# STM32H573 register map
File version: 0.4
CPU: CM33 r0p0, little endian, MPU, FPU, 4 interrupt priority bits
Registers are 32-bit, read-write, reset 0x0 unless marked. A register's access mark holds for its fields unless they carry their own. Offsets are from the block's base; [hi:lo] are bit positions; {n}, {i} and the like mark numbered series.

## TIM1 — Advanced-control timers
Base 0x40012C00
Same registers: TIM8 0x40013400, SEC_TIM1 0x50012C00, SEC_TIM8 0x50013400
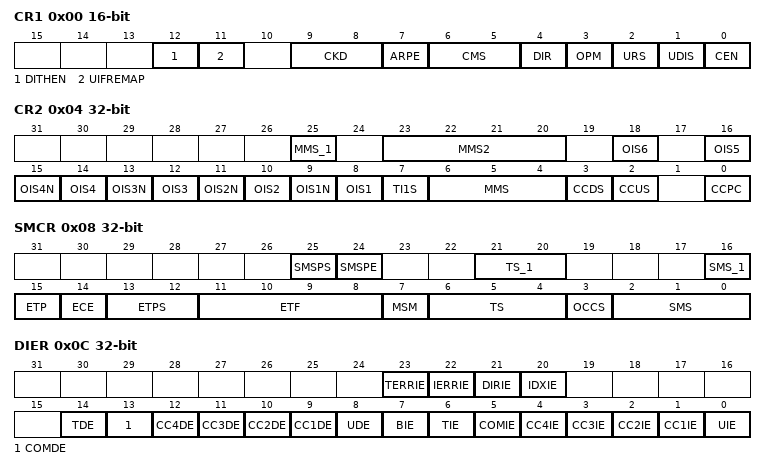
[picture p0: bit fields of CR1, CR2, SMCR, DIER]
0x00 CR1 16-bit — TIM1 control register 1
  [12] DITHEN — Dithering enable Note: The DITHEN bit can only be modified when CEN bit is reset.
  [11] UIFREMAP — UIF status bit remapping
  [9:8] CKD — Clock division This bit-field indicates the division ratio between the timer clock (tim_ker_ck) frequency and the dead-time and sampling clock (t<sub>DTS</sub>)used by the dead-time generators and the digital filters (tim_etr_in, tim_tix),
  [7] ARPE — Auto-reload preload enable
  [6:5] CMS — Center-aligned mode selection Note: It is not allowed to switch from edge-aligned mode to center-aligned mode as long as the counter is enabled (CEN=1)
  [4] DIR — Direction Note: This bit is read only when the timer is configured in Center-aligned mode or Encoder mode.
  [3] OPM — One-pulse mode
  [2] URS — Update request source This bit is set and cleared by software to select the UEV event sources. Counter overflow/underflow Setting the UG bit Update generation through the slave mode controller
  [1] UDIS — Update disable This bit is set and cleared by software to enable/disable UEV event generation. Counter overflow/underflow Setting the UG bit Update generation through the slave mode controller Buffered registers are then loaded with their preload values.
  [0] CEN — Counter enable Note: External clock, gated mode and encoder mode can work only if the CEN bit has been previously set by software. However trigger mode can set the CEN bit automatically by hardware.
0x04 CR2 — TIM1 control register 2
  [25] MMS_1 — MMS[3]
  [23:20] MMS2 — Master mode selection 2 These bits allow the information to be sent to ADC for synchronization (tim_trgo2) to be selected. The combination is as follows: Note: The clock of the slave timer or ADC must be enabled prior to receive events from the master timer, and must not be changed on-the-fly while triggers are received from the master timer.
  [18] OIS6 — Output idle state 6 (tim_oc6 output) Refer to OIS1 bit
  [16] OIS5 — Output idle state 5 (tim_oc5 output) Refer to OIS1 bit
  [15] OIS4N — Output idle state 4 (tim_oc4n output) Refer to OIS1N bit
  [14] OIS4 — Output idle state 4 (tim_oc4 output) Refer to OIS1 bit
  [13] OIS3N — Output idle state 3 (tim_oc3n output) Refer to OIS1N bit
  [12] OIS3 — Output idle state 3 (tim_oc3n output) Refer to OIS1 bit
  [11] OIS2N — Output idle state 2 (tim_oc2n output) Refer to OIS1N bit
  [10] OIS2 — Output idle state 2 (tim_oc2 output) Refer to OIS1 bit
  [9] OIS1N — Output idle state 1 (tim_oc1n output) Note: This bit can not be modified as long as LOCK level 1, 2 or 3 has been programmed (LOCK bits in TIMx_BDTR register).
  [8] OIS1 — Output idle state 1 (tim_oc1 output) Note: This bit can not be modified as long as LOCK level 1, 2 or 3 has been programmed (LOCK bits in TIMx_BDTR register).
  [7] TI1S — tim_ti1 selection
  [6:4] MMS — MMS[2:0]: Master mode selection These bits select the information to be sent in master mode to slave timers for synchronization (tim_trgo). The combination is as follows: Other codes reserved Note: The clock of the slave timer or ADC must be enabled prior to receive events from the master timer, and must not be changed on-the-fly while triggers are received from the master timer.
  [3] CCDS — Capture/compare DMA selection
  [2] CCUS — Capture/compare control update selection Note: This bit acts only on channels that have a complementary output.
  [0] CCPC — Capture/compare preloaded control Note: This bit acts only on channels that have a complementary output.
0x08 SMCR — TIM1 slave mode control register
  [25] SMSPS — SMS preload source This bit selects whether the events that triggers the SMS[3:0] bitfield transfer from preload to active
  [24] SMSPE — SMS preload enable This bit selects whether the SMS[3:0] bitfield is preloaded
  [21:20] TS_1 — TS[4:3]
  [16] SMS_1 — SMS[3]
  [15] ETP — External trigger polarity This bit selects whether tim_etr_in or tim_etr_in is used for trigger operations
  [14] ECE — External clock enable This bit enables External clock mode 2. Note: Setting the ECE bit has the same effect as selecting external clock mode 1 with tim_trgi connected to tim_etrf (SMS=111 and TS=00111). It is possible to simultaneously use external clock mode 2 with the following slave modes: reset mode, gated mode and trigger mode. Nevertheless, tim_trgi must not be connected to tim_etrf in this case (TS bits must not be 00111). Note: If external clock mode 1 and external clock mode 2 are enabled at the same time, the external clock input is tim_etrf.
  [13:12] ETPS — External trigger prescaler External trigger signal tim_etrp frequency must be at most 1/4 of TIMxCLK frequency. A prescaler can be enabled to reduce tim_etrp frequency. It is useful when inputting fast external clocks on tim_etr_in.
  [11:8] ETF — External trigger filter This bit-field then defines the frequency used to sample tim_etrp signal and the length of the digital filter applied to tim_etrp. The digital filter is made of an event counter in which N consecutive events are needed to validate a transition on the output:
  [7] MSM — Master/slave mode
  [6:4] TS — TS[2:0]: Trigger selection This bitfield is combined with TS[4:3] bits. This bit-field selects the trigger input to be used to synchronize the counter. Others: Reserved See Table 605: TIMx internal trigger connection for more details on tim_itrx meaning for each Timer. Note: These bits must be changed only when they are not used (e.g. when SMS=000) to avoid wrong edge detections at the transition.
  [3] OCCS — OCREF clear selection This bit is used to select the OCREF clear source.
  [2:0] SMS — SMS[2:0]: Slave mode selection When external signals are selected the active edge of the trigger signal (tim_trgi) is linked to the polarity selected on the external input (see Input Control register and Control Register description. Note: The gated mode must not be used if tim_ti1f_ed is selected as the trigger input (TS=00100). Indeed, tim_ti1f_ed outputs 1 pulse for each transition on TI1F, whereas the gated mode checks the level of the trigger signal. Note: The clock of the slave peripherals (timer, ADC, ...) receiving the tim_trgo or the tim_trgo2 signals must be enabled prior to receive events from the master timer, and the clock frequency (prescaler) must not be changed on-the-fly while triggers are received from the master timer.
0x0C DIER — TIM1 DMA/interrupt enable register
  [23] TERRIE — Transition error interrupt enable
  [22] IERRIE — Index error interrupt enable
  [21] DIRIE — Direction change interrupt enable
  [20] IDXIE — Index interrupt enable
  [14] TDE — Trigger DMA request enable
  [13] COMDE — COM DMA request enable
  [n+8] CC{n}DE (n=1..4) — Capture/compare {n} DMA request enable
  [8] UDE — Update DMA request enable
  [7] BIE — Break interrupt enable
  [6] TIE — Trigger interrupt enable
  [5] COMIE — COM interrupt enable
  [n] CC{n}IE (n=1..4) — Capture/compare {n} interrupt enable
  [0] UIE — Update interrupt enable
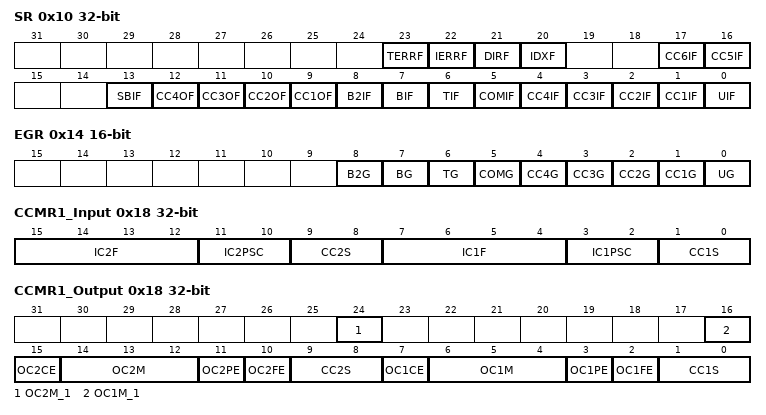
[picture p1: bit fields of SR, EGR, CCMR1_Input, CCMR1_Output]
0x10 SR — TIM1 status register
  [23] TERRF — Transition error interrupt flag This flag is set by hardware when a transition error is detected in encoder mode. It is cleared by software by writing it to ‘0’.
  [22] IERRF — Index error interrupt flag This flag is set by hardware when an index error is detected. It is cleared by software by writing it to ‘0’.
  [21] DIRF — Direction change interrupt flag This flag is set by hardware when the direction changes in encoder mode (DIR bit value in TIMx_CR is changing). It is cleared by software by writing it to ‘0’.
  [20] IDXF — Index interrupt flag This flag is set by hardware when an index event is detected. It is cleared by software by writing it to ‘0’.
  [17] CC6IF — Compare 6 interrupt flag Refer to CC1IF description Note: Channel 6 can only be configured as output.
  [16] CC5IF — Compare 5 interrupt flag Refer to CC1IF description Note: Channel 5 can only be configured as output.
  [13] SBIF — System break interrupt flag This flag is set by hardware as soon as the system break input goes active. It can be cleared by software if the system break input is not active. This flag must be reset to re-start PWM operation.
  [12] CC4OF — Capture/compare 4 overcapture flag Refer to CC1OF description
  [11] CC3OF — Capture/compare 3 overcapture flag Refer to CC1OF description
  [10] CC2OF — Capture/compare 2 overcapture flag Refer to CC1OF description
  [9] CC1OF — Capture/compare 1 overcapture flag This flag is set by hardware only when the corresponding channel is configured in input capture mode. It is cleared by software by writing it to ‘0’.
  [8] B2IF — Break 2 interrupt flag This flag is set by hardware as soon as the break 2 input goes active. It can be cleared by software if the break 2 input is not active.
  [7] BIF — Break interrupt flag This flag is set by hardware as soon as the break input goes active. It can be cleared by software if the break input is not active.
  [6] TIF — Trigger interrupt flag This flag is set by hardware on the TRG trigger event (active edge detected on tim_trgi input when the slave mode controller is enabled in all modes but gated mode. It is set when the counter starts or stops when gated mode is selected. It is cleared by software.
  [5] COMIF — COM interrupt flag This flag is set by hardware on COM event (when capture/compare Control bits - CCxE, CCxNE, OCxM - have been updated). It is cleared by software.
  [4] CC4IF — Capture/compare 4 interrupt flag Refer to CC1IF description
  [3] CC3IF — Capture/compare 3 interrupt flag Refer to CC1IF description
  [2] CC2IF — Capture/compare 2 interrupt flag Refer to CC1IF description
  [1] CC1IF — Capture/compare 1 interrupt flag This flag is set by hardware. It is cleared by software (input capture or output compare mode) or by reading the TIMx_CCR1 register (input capture mode only). If channel CC1 is configured as output: this flag is set when the content of the counter TIMx_CNT matches the content of the TIMx_CCR1 register. When the content of TIMx_CCR1 is greater than the content of TIMx_ARR, the CC1IF bit goes high on the counter overflow (in up-counting and up/down-counting modes) or underflow (in downcounting mode). There are 3 possible options for flag setting in center-aligned mode, refer to the CMS bits in the TIMx_CR1 register for the full description. If channel CC1 is configured as input: this bit is set when counter value has been captured in TIMx_CCR1 register (an edge has been detected on IC1, as per the edge sensitivity defined with the CC1P and CC1NP bits setting, in TIMx_CCER).
  [0] UIF — Update interrupt flag This bit is set by hardware on an update event. It is cleared by software. At overflow or underflow regarding the repetition counter value (update if repetition counter = 0) and if the UDIS=0 in the TIMx_CR1 register. When CNT is reinitialized by software using the UG bit in TIMx_EGR register, if URS=0 and UDIS=0 in the TIMx_CR1 register. When CNT is reinitialized by a trigger event (refer to Section 65.6.3: TIM1 slave mode control register (TIM1_SMCR)), if URS=0 and UDIS=0 in the TIMx_CR1 register.
0x14 EGR 16-bit wo — TIM1 event generation register
  [8] B2G — Break 2 generation This bit is set by software in order to generate an event, it is automatically cleared by hardware.
  [7] BG — Break generation This bit is set by software in order to generate an event, it is automatically cleared by hardware.
  [6] TG — Trigger generation This bit is set by software in order to generate an event, it is automatically cleared by hardware.
  [5] COMG — Capture/compare control update generation This bit can be set by software, it is automatically cleared by hardware Note: This bit acts only on channels having a complementary output.
  [4] CC4G — Capture/compare 4 generation Refer to CC1G description
  [3] CC3G — Capture/compare 3 generation Refer to CC1G description
  [2] CC2G — Capture/compare 2 generation Refer to CC1G description
  [1] CC1G — Capture/compare 1 generation This bit is set by software in order to generate an event, it is automatically cleared by hardware. If channel CC1 is configured as output: CC1IF flag is set, Corresponding interrupt or DMA request is sent if enabled. If channel CC1 is configured as input: The current value of the counter is captured in TIMx_CCR1 register. The CC1IF flag is set, the corresponding interrupt or DMA request is sent if enabled. The CC1OF flag is set if the CC1IF flag was already high.
  [0] UG — Update generation This bit can be set by software, it is automatically cleared by hardware.
0x18 CCMR1_Input — TIM1 capture/compare mode register 1 [alternate]
  [15:12] IC2F — Input capture 2 filter
  [11:10] IC2PSC — Input capture 2 prescaler
  [9:8] CC2S — Capture/compare 2 selection This bit-field defines the direction of the channel (input/output) as well as the used input. Note: CC2S bits are writable only when the channel is OFF (CC2E = ‘0’ in TIMx_CCER).
  [7:4] IC1F — Input capture 1 filter This bit-field defines the frequency used to sample tim_ti1 input and the length of the digital filter applied to tim_ti1. The digital filter is made of an event counter in which N consecutive events are needed to validate a transition on the output:
  [3:2] IC1PSC — Input capture 1 prescaler This bit-field defines the ratio of the prescaler acting on CC1 input (tim_ic1). The prescaler is reset as soon as CC1E=’0’ (TIMx_CCER register).
  [1:0] CC1S — Capture/compare 1 Selection This bit-field defines the direction of the channel (input/output) as well as the used input. Note: CC1S bits are writable only when the channel is OFF (CC1E = ‘0’ in TIMx_CCER).
0x18 CCMR1_Output (alternate view of TIM1_CCMR1_Input) — TIM1 capture/compare mode register 1 [alternate]
  [24] OC2M_1 — OC2M[3]
  [16] OC1M_1 — OC1M[3]
  [15] OC2CE — Output compare 2 clear enable
  [14:12] OC2M — OC2M[2:0]: Output compare 2 mode
  [11] OC2PE — Output compare 2 preload enable
  [10] OC2FE — Output compare 2 fast enable
  [9:8] CC2S — Capture/compare 2 selection This bit-field defines the direction of the channel (input/output) as well as the used input. Note: CC2S bits are writable only when the channel is OFF (CC2E = ‘0’ in TIMx_CCER).
  [7] OC1CE — Output compare 1 clear enable
  [6:4] OC1M — OC1M[2:0]: Output compare 1 mode These bits define the behavior of the output reference signal tim_oc1ref from which tim_oc1 and tim_oc1n are derived. tim_oc1ref is active high whereas tim_oc1 and tim_oc1n active level depends on CC1P and CC1NP bits. Note: These bits can not be modified as long as LOCK level 3 has been programmed (LOCK bits in TIMx_BDTR register) and CC1S=’00’ (the channel is configured in output). Note: In PWM mode, the OCREF level changes only when the result of the comparison changes or when the output compare mode switches from “frozen” mode to “PWM” mode. Note: On channels having a complementary output, this bit field is preloaded. If the CCPC bit is set in the TIMx_CR2 register then the OC1M active bits take the new value from the preloaded bits only when a COM event is generated.
  [3] OC1PE — Output compare 1 preload enable Note: These bits can not be modified as long as LOCK level 3 has been programmed (LOCK bits in TIMx_BDTR register) and CC1S=’00’ (the channel is configured in output).
  [2] OC1FE — Output compare 1 fast enable This bit decreases the latency between a trigger event and a transition on the timer output. It must be used in one-pulse mode (OPM bit set in TIMx_CR1 register), to have the output pulse starting as soon as possible after the starting trigger.
  [1:0] CC1S — Capture/compare 1 selection This bit-field defines the direction of the channel (input/output) as well as the used input. Note: CC1S bits are writable only when the channel is OFF (CC1E = ‘0’ in TIMx_CCER).
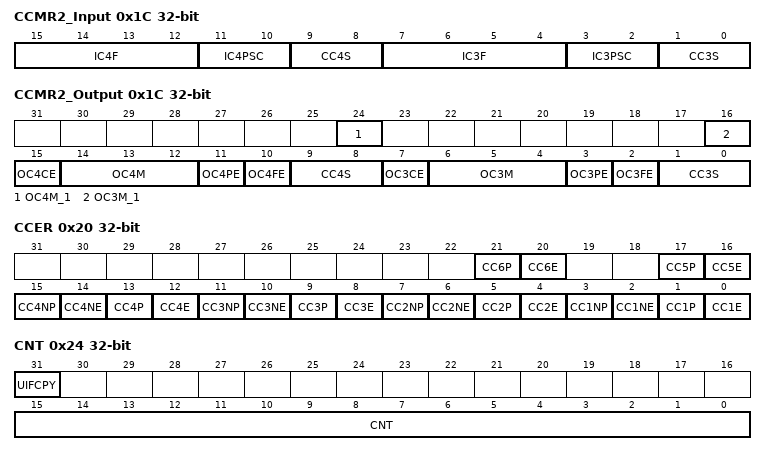
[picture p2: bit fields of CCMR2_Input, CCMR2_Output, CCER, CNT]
0x1C CCMR2_Input — TIM1 capture/compare mode register 2 [alternate]
  [15:12] IC4F — Input capture 4 filter
  [11:10] IC4PSC — Input capture 4 prescaler
  [9:8] CC4S — Capture/compare 4 selection This bit-field defines the direction of the channel (input/output) as well as the used input. Note: CC4S bits are writable only when the channel is OFF (CC4E = ‘0’ in TIMx_CCER).
  [7:4] IC3F — Input capture 3 filter
  [3:2] IC3PSC — Input capture 3 prescaler
  [1:0] CC3S — Capture/compare 3 selection This bit-field defines the direction of the channel (input/output) as well as the used input. Note: CC3S bits are writable only when the channel is OFF (CC3E = ‘0’ in TIMx_CCER).
0x1C CCMR2_Output (alternate view of TIM1_CCMR2_Input) — TIM1 capture/compare mode register 2 [alternate]
  [24] OC4M_1 — OC4M[3]
  [16] OC3M_1 — OC3M[3]
  [15] OC4CE — Output compare 4 clear enable
  [14:12] OC4M — OC4M[2:0]: Output compare 4 mode Refer to OC3M[3:0] bit description
  [11] OC4PE — Output compare 4 preload enable
  [10] OC4FE — Output compare 4 fast enable
  [9:8] CC4S — Capture/compare 4 selection This bit-field defines the direction of the channel (input/output) as well as the used input. Note: CC4S bits are writable only when the channel is OFF (CC4E = ‘0’ in TIMx_CCER).
  [7] OC3CE — Output compare 3 clear enable
  [6:4] OC3M — OC3M[2:0]: Output compare 3 mode These bits define the behavior of the output reference signal tim_oc3ref from which tim_oc3 and tim_oc3n are derived. tim_oc3ref is active high whereas tim_oc3 and tim_oc3n active level depends on CC3P and CC3NP bits. Note: These bits can not be modified as long as LOCK level 3 has been programmed (LOCK bits in TIMx_BDTR register) and CC1S=’00’ (the channel is configured in output). Note: In PWM mode, the OCREF level changes only when the result of the comparison changes or when the output compare mode switches from “frozen” mode to “PWM” mode. On channels having a complementary output, this bit field is preloaded. If the CCPC bit is set in the TIMx_CR2 register then the OC3M active bits take the new value from the preloaded bits only when a COM event is generated.
  [3] OC3PE — Output compare 3 preload enable
  [2] OC3FE — Output compare 3 fast enable
  [1:0] CC3S — Capture/compare 3 selection This bit-field defines the direction of the channel (input/output) as well as the used input. Note: CC3S bits are writable only when the channel is OFF (CC3E = ‘0’ in TIMx_CCER).
0x20 CCER — TIM1 capture/compare enable register
  [4n-3] CC{n}P (n=2..6) — Capture/compare {n} output polarity Refer to CC1P description
  [4n-4] CC{n}E (n=2..6) — Capture/compare {n} output enable Refer to CC1E description
  [15] CC4NP — Capture/compare 4 complementary output polarity Refer to CC1NP description
  [14] CC4NE — Capture/compare 4 complementary output enable Refer to CC1NE description
  [11] CC3NP — Capture/compare 3 complementary output polarity Refer to CC1NP description
  [10] CC3NE — Capture/compare 3 complementary output enable Refer to CC1NE description
  [7] CC2NP — Capture/compare 2 complementary output polarity Refer to CC1NP description
  [6] CC2NE — Capture/compare 2 complementary output enable Refer to CC1NE description
  [3] CC1NP — Capture/compare 1 complementary output polarity CC1 channel configured as output: CC1 channel configured as input: This bit is used in conjunction with CC1P to define the polarity of tim_ti1fp1 and tim_ti2fp1. Refer to CC1P description. Note: This bit is not writable as soon as LOCK level 2 or 3 has been programmed (LOCK bits in TIMx_BDTR register) and CC1S=”00” (channel configured as output). Note: On channels having a complementary output, this bit is preloaded. If the CCPC bit is set in the TIMx_CR2 register then the CC1NP active bit takes the new value from the preloaded bit only when a Commutation event is generated.
  [2] CC1NE — Capture/compare 1 complementary output enable Note: On channels having a complementary output, this bit is preloaded. If the CCPC bit is set in the TIMx_CR2 register then the CC1NE active bit takes the new value from the preloaded bit only when a Commutation event is generated.
  [1] CC1P — Capture/compare 1 output polarity When CC1 channel is configured as input, both CC1NP/CC1P bits select the active polarity of TI1FP1 and TI2FP1 for trigger or capture operations. CC1NP=0, CC1P=0: non-inverted/rising edge. The circuit is sensitive to TIxFP1 rising edge (capture or trigger operations in reset, external clock or trigger mode), TIxFP1 is not inverted (trigger operation in gated mode or encoder mode). CC1NP=0, CC1P=1: inverted/falling edge. The circuit is sensitive to TIxFP1 falling edge (capture or trigger operations in reset, external clock or trigger mode), TIxFP1 is inverted (trigger operation in gated mode or encoder mode). CC1NP=1, CC1P=1: non-inverted/both edges/ The circuit is sensitive to both TIxFP1 rising and falling edges (capture or trigger operations in reset, external clock or trigger mode), TIxFP1is not inverted (trigger operation in gated mode). This configuration must not be used in encoder mode. CC1NP=1, CC1P=0: the configuration is reserved, it must not be used. Note: This bit is not writable as soon as LOCK level 2 or 3 has been programmed (LOCK bits in TIMx_BDTR register). Note: On channels having a complementary output, this bit is preloaded. If the CCPC bit is set in the TIMx_CR2 register then the CC1P active bit takes the new value from the preloaded bit only when a Commutation event is generated.
  [0] CC1E — Capture/compare 1 output enable When CC1 channel is configured as output, the OC1 level depends on MOE, OSSI, OSSR, OIS1, OIS1N and CC1NE bits, regardless of the CC1E bits state. Refer to Table 619 for details. Note: On channels having a complementary output, this bit is preloaded. If the CCPC bit is set in the TIMx_CR2 register then the CC1E active bit takes the new value from the preloaded bit only when a Commutation event is generated.
0x24 CNT access per field — TIM1 counter
  [31] UIFCPY ro — UIF copy This bit is a read-only copy of the UIF bit of the TIMx_ISR register. If the UIFREMAP bit in the TIMxCR1 is reset, bit 31 is reserved and read at 0.
  [15:0] CNT rw — Counter value Non-dithering mode (DITHEN = 0) The register holds the counter value. Dithering mode (DITHEN = 1) The register only holds the non-dithered part in CNT[15:0]. The fractional part is not available.
0x28 PSC 16-bit — TIM1 prescaler
  [15:0] PSC — Prescaler value The counter clock frequency (f<sub>tim_cnt_ck</sub>) is equal to f<sub>tim_psc_ck</sub> / (PSC[15:0] + 1). PSC contains the value to be loaded in the active prescaler register at each update event (including when the counter is cleared through UG bit of TIMx_EGR register or through trigger controller when configured in “reset mode”).
0x2C ARR reset 0xFFFF — TIM1 auto-reload register
  [19:0] ARR — Auto-reload value ARR is the value to be loaded in the actual auto-reload register. Refer to the Section 65.3.3: Time-base unit on page 4457 for more details about ARR update and behavior. The counter is blocked while the auto-reload value is null. Non-dithering mode (DITHEN = 0) The register holds the auto-reload value. Dithering mode (DITHEN = 1) The register holds the integer part in ARR[19:4]. The ARR[3:0] bitfield contains the dithered part.
0x30 RCR 16-bit — TIM1 repetition counter register
  [15:0] REP — Repetition counter reload value This bitfield defines the update rate of the compare registers (i.e. periodic transfers from preload to active registers) when preload registers are enable. It also defines the update interrupt generation rate, if this interrupt is enable. When the repetition down-counter reaches zero, an update event is generated and it restarts counting from REP value. As the repetition counter is reloaded with REP value only at the repetition update event UEV, any write to the TIMx_RCR register is not taken in account until the next repetition update event. It means in PWM mode (REP+1) corresponds to: the number of PWM periods in edge-aligned mode the number of half PWM period in center-aligned mode.
0x34 CCR1 — TIM1 capture/compare register 1
  [19:0] CCR1 — Capture/compare 1 value If channel CC1 is configured as output: CCR1 is the value to be loaded in the actual capture/compare 1 register (preload value). It is loaded permanently if the preload feature is not selected in the TIMx_CCMR1 register (bit OC1PE). Else the preload value is copied in the active capture/compare 1 register when an update event occurs. The active capture/compare register contains the value to be compared to the counter TIMx_CNT and signaled on tim_oc1 output. Non-dithering mode (DITHEN = 0) The register holds the compare value in CCR1[15:0]. The CCR1[19:16] bits are reset. Dithering mode (DITHEN = 1) The register holds the integer part in CCR1[19:4]. The CCR1[3:0] bitfield contains the dithered part. If channel CC1 is configured as input: CR1 is the counter value transferred by the last input capture 1 event (tim_ic1). The TIMx_CCR1 register is read-only and cannot be programmed. Non-dithering mode (DITHEN = 0) The register holds the capture value in CCR1[15:0]. The CCR1[19:16] bits are reset. Dithering mode (DITHEN = 1) The register holds the capture in CCR1[19:4]. The CCR1[3:0] bits are reset.
0x38 CCR2 — TIM1 capture/compare register 2
  [19:0] CCR2 — Capture/compare 2 value If channel CC2 is configured as output: CCR2 is the value to be loaded in the actual capture/compare 2 register (preload value). It is loaded permanently if the preload feature is not selected in the TIMx_CCMR1 register (bit OC2PE). Else the preload value is copied in the active capture/compare 2 register when an update event occurs. The active capture/compare register contains the value to be compared to the counter TIMx_CNT and signaled on tim_oc2 output. Non-dithering mode (DITHEN = 0) The register holds the compare value in CCR2[15:0]. The CCR2[19:16] bits are reset. Dithering mode (DITHEN = 1) The register holds the integer part in CCR2[19:4]. The CCR2[3:0] bitfield contains the dithered part. If channel CC2 is configured as input: CCR2 is the counter value transferred by the last input capture 2 event (tim_ic2). The TIMx_CCR2 register is read-only and cannot be programmed. Non-dithering mode (DITHEN = 0) The register holds the capture value in CCR2[15:0]. The CCR2[19:16] bits are reset. Dithering mode (DITHEN = 1) The register holds the capture in CCR2[19:4]. The CCR2[3:0] bits are reset.
0x3C CCR3 — TIM1 capture/compare register 3
  [19:0] CCR3 — Capture/compare value If channel CC3 is configured as output: CCR3 is the value to be loaded in the actual capture/compare 3 register (preload value). It is loaded permanently if the preload feature is not selected in the TIMx_CCMR2 register (bit OC3PE). Else the preload value is copied in the active capture/compare 3 register when an update event occurs. The active capture/compare register contains the value to be compared to the counter TIMx_CNT and signaled on tim_oc3 output. Non-dithering mode (DITHEN = 0) The register holds the compare value in CCR3[15:0]. The CCR3[19:16] bits are reset. Dithering mode (DITHEN = 1) The register holds the integer part in CCR3[19:4]. The CCR3[3:0] bitfield contains the dithered part. If channel CC3 is configured as input: CCR3 is the counter value transferred by the last input capture 3 event (tim_ic3). The TIMx_CCR3 register is read-only and cannot be programmed. Non-dithering mode (DITHEN = 0) The register holds the capture value in CCR3[15:0]. The CCR3[19:16] bits are reset. Dithering mode (DITHEN = 1) The register holds the capture in CCR3[19:4]. The CCR3[3:0] bits are reset.
0x40 CCR4 — TIM1 capture/compare register 4
  [19:0] CCR4 — Capture/compare value If channel CC4 is configured as output: CCR4 is the value to be loaded in the actual capture/compare 4 register (preload value). It is loaded permanently if the preload feature is not selected in the TIMx_CCMR2 register (bit OC4PE). Else the preload value is copied in the active capture/compare 4 register when an update event occurs. The active capture/compare register contains the value to be compared to the counter TIMx_CNT and signalled on tim_oc4 output. Non-dithering mode (DITHEN = 0) The register holds the compare value in CCR4[15:0]. The CCR4[19:16] bits are reset. Dithering mode (DITHEN = 1) The register holds the integer part in CCR4[19:4]. The CCR4[3:0] bitfield contains the dithered part. If channel CC4 is configured as input: CCR4 is the counter value transferred by the last input capture 4 event (tim_ic4). The TIMx_CCR4 register is read-only and cannot be programmed. Non-dithering mode (DITHEN = 0) The register holds the capture value in CCR4[15:0]. The CCR4[19:16] bits are reset. Dithering mode (DITHEN = 1) The register holds the capture in CCR4[19:4]. The CCR4[3:0] bits are reset.
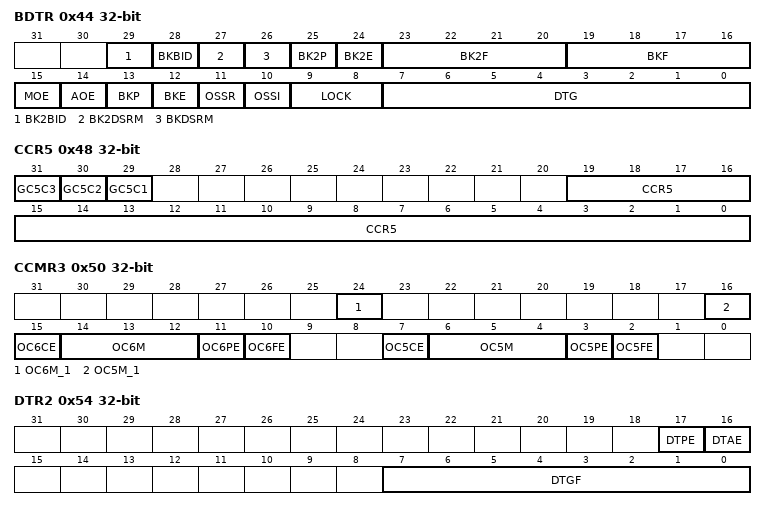
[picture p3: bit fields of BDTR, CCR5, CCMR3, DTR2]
0x44 BDTR — TIM1 break and dead-time register
  [29] BK2BID — Break2 bidirectional Refer to BKBID description
  [28] BKBID — Break bidirectional In the bidirectional mode (BKBID bit set to 1), the break input is configured both in input mode and in open drain output mode. Any active break event asserts a low logic level on the Break input to indicate an internal break event to external devices. Note: This bit cannot be modified as long as LOCK level 1 has been programmed (LOCK bits in TIMx_BDTR register). Note: Any write operation to this bit takes a delay of 1 APB clock cycle to become effective.
  [27] BK2DSRM — Break2 disarm Refer to BKDSRM description
  [26] BKDSRM — Break disarm This bit is cleared by hardware when no break source is active. The BKDSRM bit must be set by software to release the bidirectional output control (open-drain output in Hi-Z state) and then be polled it until it is reset by hardware, indicating that the fault condition has disappeared. Note: Any write operation to this bit takes a delay of 1 APB clock cycle to become effective.
  [25] BK2P — Break 2 polarity Note: This bit cannot be modified as long as LOCK level 1 has been programmed (LOCK bits in TIMx_BDTR register). Note: Any write operation to this bit takes a delay of 1 APB clock cycle to become effective.
  [24] BK2E — Break 2 enable This bit enables the complete break 2 protection (including all sources connected to bk_acth and BKIN sources, as per Figure 635: Break and Break2 circuitry overview). Note: The BRKIN2 must only be used with OSSR = OSSI = 1. Note: This bit cannot be modified when LOCK level 1 has been programmed (LOCK bits in TIMx_BDTR register). Note: Any write operation to this bit takes a delay of 1 APB clock cycle to become effective.
  [23:20] BK2F — Break 2 filter This bit-field defines the frequency used to sample tim_brk2 input and the length of the digital filter applied to tim_brk2. The digital filter is made of an event counter in which N consecutive events are needed to validate a transition on the output: Note: This bit cannot be modified when LOCK level 1 has been programmed (LOCK bits in TIMx_BDTR register).
  [19:16] BKF — Break filter This bit-field defines the frequency used to sample tim_brk input and the length of the digital filter applied to tim_brk. The digital filter is made of an event counter in which N consecutive events are needed to validate a transition on the output: Note: This bit cannot be modified when LOCK level 1 has been programmed (LOCK bits in TIMx_BDTR register).
  [15] MOE — Main output enable This bit is cleared asynchronously by hardware as soon as one of the break inputs is active (tim_brk or tim_brk2). It is set by software or automatically depending on the AOE bit. It is acting only on the channels which are configured in output. In response to a break event or if MOE is written to 0: OC and OCN outputs are disabled or forced to idle state depending on the OSSI bit. See OC/OCN enable description for more details (Section 65.6.11: TIM1 capture/compare enable register (TIM1_CCER)).
  [14] AOE — Automatic output enable Note: This bit can not be modified as long as LOCK level 1 has been programmed (LOCK bits in TIMx_BDTR register).
  [13] BKP — Break polarity Note: This bit can not be modified as long as LOCK level 1 has been programmed (LOCK bits in TIMx_BDTR register). Note: Any write operation to this bit takes a delay of 1 APB clock cycle to become effective.
  [12] BKE — Break enable This bit enables the complete break protection (including all sources connected to bk_acth and BKIN sources, as per Figure 635: Break and Break2 circuitry overview). Note: This bit cannot be modified when LOCK level 1 has been programmed (LOCK bits in TIMx_BDTR register). Note: Any write operation to this bit takes a delay of 1 APB clock cycle to become effective.
  [11] OSSR — Off-state selection for Run mode This bit is used when MOE=1 on channels having a complementary output which are configured as outputs. OSSR is not implemented if no complementary output is implemented in the timer. See OC/OCN enable description for more details (Section 65.6.11: TIM1 capture/compare enable register (TIM1_CCER)). Note: This bit can not be modified as soon as the LOCK level 2 has been programmed (LOCK bits in TIMx_BDTR register).
  [10] OSSI — Off-state selection for idle mode This bit is used when MOE=0 due to a break event or by a software write, on channels configured as outputs. See OC/OCN enable description for more details (Section 65.6.11: TIM1 capture/compare enable register (TIM1_CCER)). Note: This bit can not be modified as soon as the LOCK level 2 has been programmed (LOCK bits in TIMx_BDTR register).
  [9:8] LOCK — Lock configuration These bits offer a write protection against software errors. Note: The LOCK bits can be written only once after the reset. Once the TIMx_BDTR register has been written, their content is frozen until the next reset.
  [7:0] DTG — Dead-time generator setup This bit-field defines the duration of the dead-time inserted between the complementary outputs. DT correspond to this duration. DTG[7:5]=0xx => DT=DTG[7:0]x t<sub>dtg</sub> with t<sub>dtg</sub>=t<sub>DTS</sub>. DTG[7:5]=10x => DT=(64+DTG[5:0])xt<sub>dtg</sub> with T<sub>dtg</sub>=2xt<sub>DTS</sub>. DTG[7:5]=110 => DT=(32+DTG[4:0])xt<sub>dtg</sub> with T<sub>dtg</sub>=8xt<sub>DTS</sub>. DTG[7:5]=111 => DT=(32+DTG[4:0])xt<sub>dtg</sub> with T<sub>dtg</sub>=16xt<sub>DTS</sub>. Example if T<sub>DTS</sub>=125ns (8MHz), dead-time possible values are: 0 to 15875 ns by 125 ns steps, 16 us to 31750 ns by 250 ns steps, 32 us to 63us by 1 us steps, 64 us to 126 us by 2 us steps Note: This bit-field can not be modified as long as LOCK level 1, 2 or 3 has been programmed (LOCK bits in TIMx_BDTR register).
0x48 CCR5 — TIM1 capture/compare register 5
  [31] GC5C3 — Group channel 5 and channel 3 Distortion on channel 3 output: This bit can either have immediate effect or be preloaded and taken into account after an update event (if preload feature is selected in TIMxCCMR2). Note: it is also possible to apply this distortion on combined PWM signals.
  [30] GC5C2 — Group channel 5 and channel 2 Distortion on channel 2 output: This bit can either have immediate effect or be preloaded and taken into account after an update event (if preload feature is selected in TIMxCCMR1). Note: it is also possible to apply this distortion on combined PWM signals.
  [29] GC5C1 — Group channel 5 and channel 1 Distortion on channel 1 output: This bit can either have immediate effect or be preloaded and taken into account after an update event (if preload feature is selected in TIMxCCMR1). Note: it is also possible to apply this distortion on combined PWM signals.
  [19:0] CCR5 — Capture/compare 5 value CCR5 is the value to be loaded in the actual capture/compare 5 register (preload value). It is loaded permanently if the preload feature is not selected in the TIMx_CCMR3 register (bit OC5PE). Else the preload value is copied in the active capture/compare 5 register when an update event occurs. The active capture/compare register contains the value to be compared to the counter TIMx_CNT and signaled on tim_oc5 output. Non-dithering mode (DITHEN = 0) The register holds the compare value in CCR5[15:0]. The CCR5[19:16] bits are reset. Dithering mode (DITHEN = 1) The register holds the integer part in CCR5[19:4]. The CCR5[3:0] bitfield contains the dithered part.
0x4C CCR6 — TIM1 capture/compare register 6
  [19:0] CCR6 — Capture/compare 6 value CCR6 is the value to be loaded in the actual capture/compare 6 register (preload value). It is loaded permanently if the preload feature is not selected in the TIMx_CCMR3 register (bit OC6PE). Else the preload value is copied in the active capture/compare 6 register when an update event occurs. The active capture/compare register contains the value to be compared to the counter TIMx_CNT and signaled on tim_oc6 output. Non-dithering mode (DITHEN = 0) The register holds the compare value in CCR6[15:0]. The CCR6[19:16] bits are reset. Dithering mode (DITHEN = 1) The register holds the integer part in CCR6[19:4]. The CCR6[3:0] bitfield contains the dithered part.
0x50 CCMR3 — TIM1 capture/compare mode register 3
  [24] OC6M_1 — OC6M[3]
  [16] OC5M_1 — OC5M[3]
  [15] OC6CE — Output compare 6 clear enable
  [14:12] OC6M — OC6M[2:0]: Output compare 6 mode
  [11] OC6PE — Output compare 6 preload enable
  [10] OC6FE — Output compare 6 fast enable
  [7] OC5CE — Output compare 5 clear enable
  [6:4] OC5M — OC5M[2:0]: Output compare 5 mode
  [3] OC5PE — Output compare 5 preload enable
  [2] OC5FE — Output compare 5 fast enable
0x54 DTR2 — TIM1 timer deadtime register 2
  [17] DTPE — Deadtime preload enable Note: This bit can not be modified as long as LOCK level 1, 2 or 3 has been programmed (LOCK bits in TIMx_BDTR register).
  [16] DTAE — Deadtime asymmetric enable Note: This bit can not be modified as long as LOCK level 1, 2 or 3 has been programmed (LOCK bits in TIMx_BDTR register).
  [7:0] DTGF — Dead-time falling edge generator setup This bit-field defines the duration of the dead-time inserted between the complementary outputs, on the falling edge. DTGF[7:5]=0xx => DTF=DTGF[7:0]x t<sub>dtg</sub> with t<sub>dtg</sub>=t<sub>DTS</sub>. DTGF[7:5]=10x => DTF=(64+DTGF[5:0])xt<sub>dtg</sub> with T<sub>dtg</sub>=2xt<sub>DTS</sub>. DTGF[7:5]=110 => DTF=(32+DTGF[4:0])xt<sub>dtg</sub> with T<sub>dtg</sub>=8xt<sub>DTS</sub>. DTGF[7:5]=111 => DTF=(32+DTGF[4:0])xt<sub>dtg</sub> with T<sub>dtg</sub>=16xt<sub>DTS</sub>. Example if T<sub>DTS</sub>=125ns (8MHz), dead-time possible values are: 0 to 15875 ns by 125 ns steps, 16 us to 31750 ns by 250 ns steps, 32 us to 63us by 1 us steps, 64 us to 126 us by 2 us steps Note: This bit-field can not be modified as long as LOCK level 1, 2 or 3 has been programmed (LOCK bits in TIMx_BDTR register).
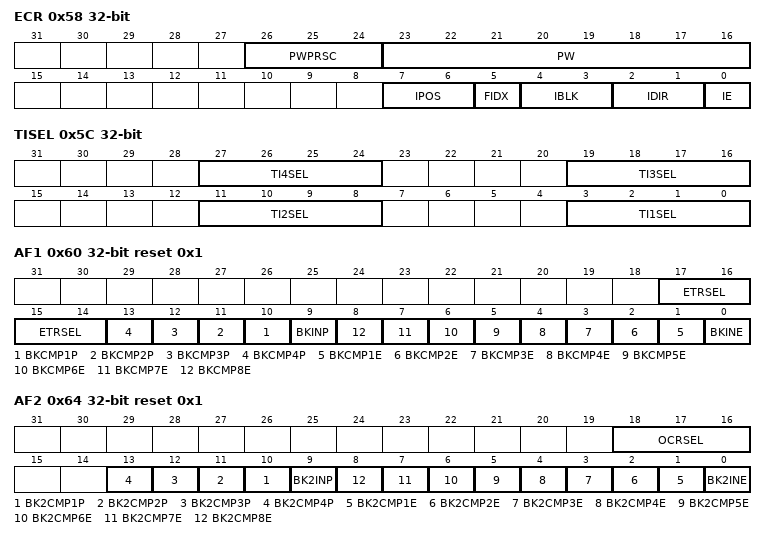
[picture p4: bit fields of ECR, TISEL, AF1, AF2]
0x58 ECR — TIM1 timer encoder control register
  [26:24] PWPRSC — Pulse width prescaler This bitfield sets the clock prescaler for the pulse generator, as following: t<sub>PWG</sub> = (2<sup>(PWPRSC[2:0])</sup>) x t<sub>tim_ker_ck</sub>
  [23:16] PW — Pulse width This bitfield defines the pulse duration, as following: t<sub>PW</sub> = PW[7:0] x t<sub>PWG</sub>
  [7:6] IPOS — Index positioning In quadrature encoder mode (SMS[3:0] = 0001, 0010, 0011, 1110, 1111), this bit indicates in which AB input configuration the Index event resets the counter. In directional clock mode or clock plus direction mode (SMS[3:0] = 1010, 1011, 1100, 1101), these bits indicates on which level the Index event resets the counter. In bidirectional clock mode, this applies for both clock inputs. x0: Index resets the counter when clock is 0 x1: Index resets the counter when clock is 1 Note: IPOS[1] bit is not significant
  [5] FIDX — First index This bit indicates if the first index only is taken into account
  [4:3] IBLK — Index blanking This bit indicates if the Index event is conditioned by the tim_ti3 input
  [2:1] IDIR — Index direction This bit indicates in which direction the Index event resets the counter. Note: The IDR[1:0] bitfield must be written when IE bit is reset (index disabled).
  [0] IE — Index enable This bit indicates if the Index event resets the counter.
0x5C TISEL — TIM1 timer input selection register
  [8n-5:8n-8] TI{n}SEL (n=1..4) — Selects tim_ti{n}[0..15] input ... Refer to Section 65.3.2: TIM1 pins and internal signals for interconnects list.
0x60 AF1 reset 0x1 — TIM1 alternate function option register 1
  [17:14] ETRSEL — etr_in source selection These bits select the etr_in input source. ... Refer to Section 65.3.2: TIM1 pins and internal signals for product specific implementation. Note: These bits can not be modified as long as LOCK level 1 has been programmed (LOCK bits in TIMx_BDTR register).
  [n+9] BKCMP{n}P (n=1..4) — tim_brk_cmp{n} input polarity This bit selects the tim_brk_cmp{n} input sensitivity. It must be programmed together with the BKP polarity bit. Note: This bit can not be modified as long as LOCK level 1 has been programmed (LOCK bits in TIMx_BDTR register).
  [9] BKINP — TIMx_BKIN input polarity This bit selects the TIMx_BKIN alternate function input sensitivity. It must be programmed together with the BKP polarity bit. Note: This bit can not be modified as long as LOCK level 1 has been programmed (LOCK bits in TIMx_BDTR register).
  [n] BKCMP{n}E (n=1..8) — tim_brk_cmp{n} enable This bit enables the tim_brk_cmp{n} for the timer’s tim_brk input. tim_brk_cmp{n} output is ‘ORed’ with the other tim_brk sources. Note: This bit can not be modified as long as LOCK level 1 has been programmed (LOCK bits in TIMx_BDTR register).
  [0] BKINE — TIMx_BKIN input enable This bit enables the TIMx_BKIN alternate function input for the timer’s tim_brk input. TIMx_BKIN input is ‘ORed’ with the other tim_brk sources. Note: This bit can not be modified as long as LOCK level 1 has been programmed (LOCK bits in TIMx_BDTR register).
0x64 AF2 reset 0x1 — TIM1 alternate function register 2
  [18:16] OCRSEL — ocref_clr source selection These bits select the ocref_clr input source. ... Refer to Section 65.3.2: TIM1 pins and internal signals for product specific information. Note: These bits can not be modified as long as LOCK level 1 has been programmed (LOCK bits in TIMx_BDTR register).
  [n+9] BK2CMP{n}P (n=1..4) — tim_brk2_cmp{n} input polarity This bit selects the tim_brk2_cmp{n} input sensitivity. It must be programmed together with the BK2P polarity bit. Note: This bit can not be modified as long as LOCK level 1 has been programmed (LOCK bits in TIMx_BDTR register).
  [9] BK2INP — TIMx_BKIN2 input polarity This bit selects the TIMx_BKIN2 alternate function input sensitivity. It must be programmed together with the BK2P polarity bit. Note: This bit can not be modified as long as LOCK level 1 has been programmed (LOCK bits in TIMx_BDTR register).
  [n] BK2CMP{n}E (n=1..8) — tim_brk2_cmp{n} enable This bit enables the tim_brk2_cmp{n} for the timer’s tim_brk2 input. tim_brk2_cmp{n} output is ‘ORed’ with the other tim_brk2 sources. Note: This bit can not be modified as long as LOCK level 1 has been programmed (LOCK bits in TIMx_BDTR register).
  [0] BK2INE — TIMx_BKIN2 input enable This bit enables the TIMx_BKIN2 alternate function input for the timer’s tim_brk2 input. TIMx_BKIN2 input is ‘ORed’ with the other tim_brk2 sources. Note: This bit can not be modified as long as LOCK level 1 has been programmed (LOCK bits in TIMx_BDTR register).
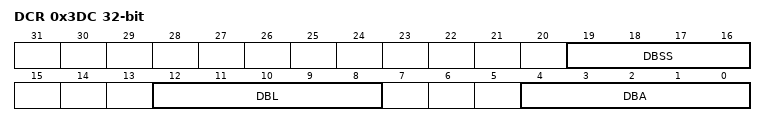
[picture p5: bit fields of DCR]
0x3DC DCR — TIM1 DMA control register
  [19:16] DBSS — DMA burst source selection This bitfield defines the interrupt source that triggers the DMA burst transfers (the timer recognizes a burst transfer when a read or a write access is done to the TIMx_DMAR address). Others: reserved
  [12:8] DBL — DMA burst length This 5-bit vector defines the length of DMA transfers (the timer recognizes a burst transfer when a read or a write access is done to the TIMx_DMAR address), i.e. the number of transfers. Transfers can be in half-words or in bytes (see example below). ... Example: Let us consider the following transfer: DBL = 7 bytes & DBA = TIM2_CR1. If DBL = 7 bytes and DBA = TIM2_CR1 represents the address of the byte to be transferred, the address of the transfer should be given by the following equation: (TIMx_CR1 address) + DBA + (DMA index), where DMA index = DBL In this example, 7 bytes are added to (TIMx_CR1 address) + DBA, which gives us the address from/to which the data are copied. In this case, the transfer is done to 7 registers starting from the following address: (TIMx_CR1 address) + DBA According to the configuration of the DMA Data Size, several cases may occur: If the DMA Data Size is configured in half-words, 16-bit data are transferred to each of the 7 registers. If the DMA Data Size is configured in bytes, the data are also transferred to 7 registers: the first register contains the first MSB byte, the second register, the first LSB byte and so on. So with the transfer Timer, one also has to specify the size of data transferred by DMA.
  [4:0] DBA — DMA base address This 5-bits vector defines the base-address for DMA transfers (when read/write access are done through the TIMx_DMAR address). DBA is defined as an offset starting from the address of the TIMx_CR1 register. Example: ...
0x3E0 DMAR — TIM1 DMA address for full transfer
  [31:0] DMAB — DMA register for burst accesses A read or write operation to the DMAR register accesses the register located at the address (TIMx_CR1 address) + (DBA + DMA index) x 4 where TIMx_CR1 address is the address of the control register 1, DBA is the DMA base address configured in TIMx_DCR register, DMA index is automatically controlled by the DMA transfer, and ranges from 0 to DBL (DBL configured in TIMx_DCR).
